VERSION ""

NS_ :

BS_:

BU_:

BO_ 3221225472 VECTOR__INDEPENDENT_SIG_MSG: 0 Vector__XXX
 SG_ fixSetG : 0|8@1+ (1,0) [0|15] "" Vector__XXX
 SG_ fixSetChrg : 0|8@1+ (1,0) [0|255] "" Vector__XXX
 SG_ NewSignal_0005 : 14|1@1+ (1,0) [0|0] "" Vector__XXX
 SG_ NewSignal_0006 : 15|1@1+ (1,0) [0|0] "" Vector__XXX
 SG_ NewSignal_0008 : 24|8@1+ (1,0) [0|0] "" Vector__XXX

BO_ 50 getData: 8 Vector__XXX
 SG_ Packet_ID M : 0|8@1+ (1,0) [0|3] "" Vector__XXX
 SG_ opMode m0 : 16|8@1+ (1,0) [0|15] "" Vector__XXX
 SG_ lowestCell m0 : 24|16@1+ (0.001,0) [0|5] "V" Vector__XXX
 SG_ highestCell m0 : 40|16@1+ (0.001,0) [0|5] "V" Vector__XXX
 SG_ highestTemp m0 : 56|8@1+ (1,0) [0|0] "C" Vector__XXX
 SG_ time_to_80_hh m1 : 16|8@1+ (1,0) [0|255] "hours" Vector__XXX
 SG_ time_to_80_mm m1 : 24|8@1+ (1,0) [0|59] "minutes" Vector__XXX
 SG_ batteryCapacity m1 : 32|8@1+ (1,0) [0|255] "Ah" Vector__XXX
 SG_ packVoltage m1 : 48|16@1+ (0.1,0) [0|1500] "V" Vector__XXX
 SG_ time_to_100_hh m2 : 16|8@1+ (1,0) [0|255] "hours" Vector__XXX
 SG_ time_to_100_mm m2 : 24|8@1+ (1,0) [0|59] "minutes" Vector__XXX
 SG_ current m2 : 32|16@1- (0.01,0) [0|2000] "A" Vector__XXX
 SG_ soc m2 : 48|8@1+ (1,0) [0|100] "" Vector__XXX
 SG_ soh m2 : 56|8@1+ (1,0) [0|100] "" Vector__XXX
 SG_ lv_error : 8|1@1+ (1,0) [0|1] "" Vector__XXX
 SG_ precharger_error : 9|1@1+ (1,0) [0|1] "" Vector__XXX
 SG_ contactor_fb_error : 10|1@1+ (1,0) [0|1] "" Vector__XXX
 SG_ battery_temp_error : 11|1@1+ (1,0) [0|1] "" Vector__XXX
 SG_ bms_comm_error : 12|1@1+ (1,0) [0|1] "" Vector__XXX
 SG_ disc_current_error : 13|1@1+ (1,0) [0|1] "" Vector__XXX
 SG_ chrg_current_error : 14|1@1+ (1,0) [0|1] "" Vector__XXX
 SG_ cell_balancing_error : 15|1@1+ (1,0) [0|1] "" Vector__XXX
 SG_ chrg_complete_flag m1 : 40|1@1+ (1,0) [0|1] "" Vector__XXX
 SG_ cv_mode m1 : 41|1@1+ (1,0) [0|1] "" Vector__XXX
 SG_ charge_current_lim m1 : 42|1@1+ (1,0) [0|1] "" Vector__XXX
 SG_ over_temp m1 : 43|1@1+ (1,0) [0|1] "" Vector__XXX
 SG_ low_soc m1 : 44|1@1+ (1,0) [0|1] "" Vector__XXX
 SG_ chiller_enable m1 : 45|1@1+ (1,0) [0|1] "" Vector__XXX
 SG_ charging m1 : 46|1@1+ (1,0) [0|1] "" Vector__XXX
 SG_ cell_hv_errpr m1 : 47|1@1+ (1,0) [0|1] "" Vector__XXX

BO_ 105 debugData: 8 Vector__XXX
 SG_ db_index M : 0|8@1+ (1,0) [0|11] "" Vector__XXX
 SG_ slave0_humidity m0 : 8|16@1+ (1,0) [0|100] "%" Vector__XXX
 SG_ slave0_temperature m0 : 24|16@1- (1,0) [-45|130] "*C" Vector__XXX
 SG_ slave0_open_wire m0 : 40|16@1+ (1,0) [0|65535] "" Vector__XXX
 SG_ slave1_humidity m1 : 8|16@1+ (1,0) [0|100] "%" Vector__XXX
 SG_ slave1_temperature m1 : 24|16@1- (1,0) [-45|130] "*C" Vector__XXX
 SG_ slave1_open_wire m1 : 40|16@1+ (1,0) [0|65535] "" Vector__XXX
 SG_ sht30_error m0 : 56|8@1+ (1,0) [0|255] "" Vector__XXX
 SG_ v_cell_0 m2 : 8|16@1+ (0.0001,0) [0|6.5535] "V" Vector__XXX
 SG_ v_cell_1 m2 : 24|16@1+ (0.0001,0) [0|6.5535] "V" Vector__XXX
 SG_ v_cell_2 m2 : 40|16@1+ (0.0001,0) [0|6.5535] "V" Vector__XXX
 SG_ v_cell_3 m3 : 8|16@1+ (0.0001,0) [0|6.5535] "V" Vector__XXX
 SG_ v_cell_4 m3 : 24|16@1+ (0.0001,0) [0|6.5535] "V" Vector__XXX
 SG_ v_cell_5 m3 : 40|16@1+ (0.0001,0) [0|6.5535] "V" Vector__XXX
 SG_ v_cell_6 m4 : 8|16@1+ (0.0001,0) [0|6.5535] "V" Vector__XXX
 SG_ v_cell_7 m4 : 24|16@1+ (0.0001,0) [0|6.5535] "V" Vector__XXX
 SG_ v_cell_8 m4 : 40|16@1+ (0.0001,0) [0|6.5535] "V" Vector__XXX
 SG_ v_cell_9 m5 : 8|16@1+ (0.0001,0) [0|6.5535] "V" Vector__XXX
 SG_ v_cell_10 m5 : 24|16@1+ (0.0001,0) [0|6.5535] "V" Vector__XXX
 SG_ v_cell_11 m5 : 40|16@1+ (0.0001,0) [0|6.5535] "V" Vector__XXX
 SG_ v_cell_12 m6 : 8|16@1+ (0.0001,0) [0|6.5535] "V" Vector__XXX
 SG_ v_cell_13 m6 : 24|16@1+ (0.0001,0) [0|6.5535] "V" Vector__XXX
 SG_ v_cell_14 m6 : 40|16@1+ (0.0001,0) [0|6.5535] "V" Vector__XXX
 SG_ v_cell_15 m7 : 8|16@1+ (0.0001,0) [0|6.5535] "V" Vector__XXX
 SG_ v_cell_16 m7 : 24|16@1+ (0.0001,0) [0|6.5535] "V" Vector__XXX
 SG_ v_cell_17 m7 : 40|16@1+ (0.0001,0) [0|6.5535] "V" Vector__XXX
 SG_ v_cell_18 m8 : 8|16@1+ (0.0001,0) [0|6.5535] "V" Vector__XXX
 SG_ v_cell_19 m8 : 24|16@1+ (0.0001,0) [0|6.5535] "V" Vector__XXX
 SG_ v_cell_20 m8 : 40|16@1+ (0.0001,0) [0|6.5535] "V" Vector__XXX
 SG_ v_cell_21 m9 : 8|16@1+ (0.0001,0) [0|6.5535] "V" Vector__XXX
 SG_ v_cell_22 m9 : 24|16@1+ (0.0001,0) [0|6.5535] "V" Vector__XXX
 SG_ v_cell_23 m9 : 40|16@1+ (0.0001,0) [0|6.5535] "V" Vector__XXX
 SG_ v_cell_24 m10 : 8|16@1+ (0.0001,0) [0|6.5535] "V" Vector__XXX
 SG_ v_cell_25 m10 : 24|16@1+ (0.0001,0) [0|6.5535] "V" Vector__XXX
 SG_ v_cell_26 m10 : 40|16@1+ (0.0001,0) [0|6.5535] "V" Vector__XXX
 SG_ v_cell_27 m11 : 8|16@1+ (0.0001,0) [0|6.5535] "V" Vector__XXX
 SG_ v_cell_28 m11 : 24|16@1+ (0.0001,0) [0|6.5535] "V" Vector__XXX
 SG_ v_cell_29 m11 : 40|16@1+ (0.0001,0) [0|6.5535] "V" Vector__XXX
 SG_ t_cell_0 m2 : 56|8@1+ (1,0) [0|255] "*C" Vector__XXX
 SG_ t_cell_1 m3 : 56|8@1+ (1,0) [0|255] "*C" Vector__XXX
 SG_ t_cell_2 m4 : 56|8@1+ (1,0) [0|255] "*C" Vector__XXX
 SG_ t_cell_3 m5 : 56|8@1+ (1,0) [0|255] "*C" Vector__XXX
 SG_ t_cell_4 m6 : 56|8@1+ (1,0) [0|255] "*C" Vector__XXX
 SG_ t_cell_5 m7 : 56|8@1+ (1,0) [0|255] "*C" Vector__XXX
 SG_ t_cell_6 m8 : 56|8@1+ (1,0) [0|255] "*C" Vector__XXX
 SG_ t_cell_7 m9 : 56|8@1+ (1,0) [0|255] "*C" Vector__XXX
 SG_ t_cell_8 m10 : 56|8@1+ (1,0) [0|255] "*C" Vector__XXX

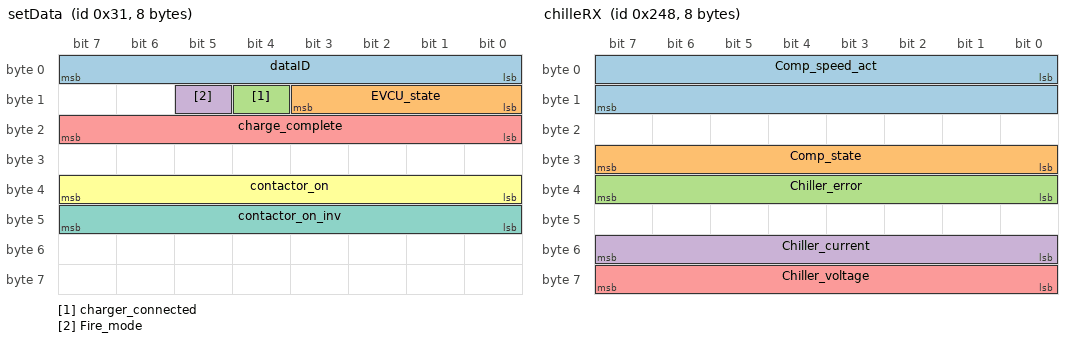
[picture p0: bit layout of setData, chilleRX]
BO_ 49 setData: 8 Vector__XXX
 SG_ dataID : 0|8@1+ (1,0) [0|2] "" Vector__XXX
 SG_ EVCU_state : 8|4@1+ (1,0) [0|8] "" Vector__XXX
 SG_ charger_connected : 12|1@1+ (1,0) [0|0] "" Vector__XXX
 SG_ Fire_mode : 13|1@1+ (1,0) [0|0] "" Vector__XXX
 SG_ charge_complete : 16|8@1+ (1,0) [0|0] "" Vector__XXX
 SG_ contactor_on : 32|8@1+ (1,0) [0|255] "" Vector__XXX
 SG_ contactor_on_inv : 40|8@1+ (1,0) [0|255] "" Vector__XXX

BO_ 584 chilleRX: 8 Vector__XXX
 SG_ Comp_speed_act : 0|16@1+ (1,0) [0|0] "" Vector__XXX
 SG_ Comp_state : 24|8@1+ (1,0) [0|0] "" Vector__XXX
 SG_ Chiller_error : 32|8@1+ (1,0) [0|0] "" Vector__XXX
 SG_ Chiller_current : 48|8@1+ (1,0) [0|0] "" Vector__XXX
 SG_ Chiller_voltage : 56|8@1+ (4,0) [0|0] "" Vector__XXX

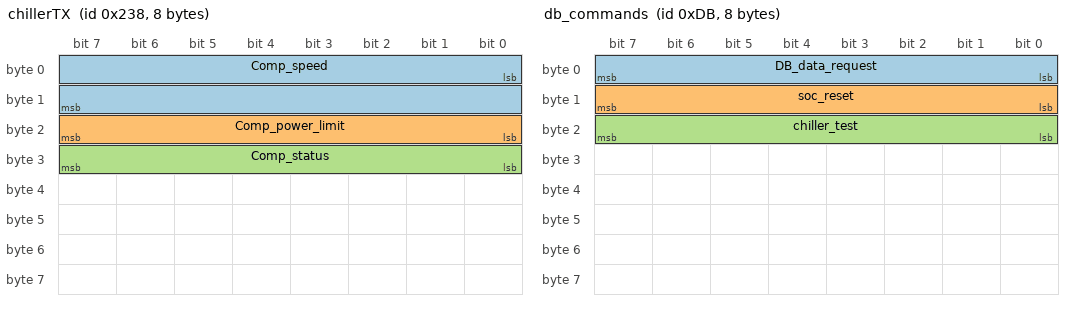
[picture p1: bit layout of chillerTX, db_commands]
BO_ 568 chillerTX: 8 Vector__XXX
 SG_ Comp_speed : 0|16@1+ (1,0) [0|0] "" Vector__XXX
 SG_ Comp_power_limit : 16|8@1+ (1,0) [0|0] "" Vector__XXX
 SG_ Comp_status : 24|8@1+ (1,0) [0|0] "" Vector__XXX

BO_ 219 db_commands: 8 Vector__XXX
 SG_ DB_data_request : 0|8@1+ (1,0) [0|0] "" Vector__XXX
 SG_ soc_reset : 8|8@1+ (1,0) [0|0] "" Vector__XXX
 SG_ chiller_test : 16|8@1+ (1,0) [0|0] "" Vector__XXX

BO_ 56 gbtData: 8 Vector__XXX
 SG_ GBT_Frame_ID M : 0|8@1+ (1,0) [0|13] "" Vector__XXX
 SG_ GBT_MaxChargeVoltage m0 : 8|16@1+ (0.1,0) [0|6553.5] "V" Vector__XXX
 SG_ GBT_MaxCellChargeVoltage m0 : 24|16@1+ (0.01,0) [0|655.35] "V" Vector__XXX
 SG_ GBT_RatedVoltage m0 : 40|16@1+ (0.1,0) [0|6553.5] "V" Vector__XXX
 SG_ GBT_BatteryType m0 : 56|8@1+ (1,0) [0|255] "" Vector__XXX
 SG_ GBT_TotalEnergy m1 : 8|16@1+ (0.1,0) [0|6553.5] "kWh" Vector__XXX
 SG_ GBT_MaxPermitTemp m1 : 24|16@1- (0.1,0) [-3276.8|3276.7] "C" Vector__XXX
 SG_ GBT_HighestCellID m1 : 56|8@1+ (1,0) [0|255] "" Vector__XXX
 SG_ GBT_LowestTemp m2 : 8|16@1- (0.1,0) [-3276.8|3276.7] "C" Vector__XXX
 SG_ GBT_LowestTempProbe m2 : 24|8@1+ (1,0) [0|255] "" Vector__XXX
 SG_ GBT_HighestTempProbe m2 : 32|8@1+ (1,0) [0|255] "" Vector__XXX
 SG_ GBT_CellVoltageState m2 : 40|2@1+ (1,0) [0|3] "" Vector__XXX
 SG_ GBT_SocState m2 : 42|2@1+ (1,0) [0|3] "" Vector__XXX
 SG_ GBT_ChargeOverCurrent m2 : 44|2@1+ (1,0) [0|3] "" Vector__XXX
 SG_ GBT_BatteryTempState m2 : 46|2@1+ (1,0) [0|3] "" Vector__XXX
 SG_ GBT_InsulationState m2 : 48|2@1+ (1,0) [0|3] "" Vector__XXX
 SG_ GBT_SingleCellVoltages m2 : 50|2@1+ (1,0) [0|3] "" Vector__XXX
 SG_ GBT_SingleCellTemps m2 : 52|2@1+ (1,0) [0|3] "" Vector__XXX
 SG_ GBT_BmsTempState m2 : 54|2@1+ (1,0) [0|3] "" Vector__XXX
 SG_ GBT_FcContactorState m2 : 56|2@1+ (1,0) [0|3] "" Vector__XXX
 SG_ GBT_LowestCellID m3 : 8|8@1+ (1,0) [0|255] "" Vector__XXX
 SG_ GBT_V_Cell_01 m4 : 8|16@1+ (0.01,0) [0|655.35] "V" Vector__XXX
 SG_ GBT_V_Cell_02 m4 : 24|16@1+ (0.01,0) [0|655.35] "V" Vector__XXX
 SG_ GBT_V_Cell_03 m4 : 40|16@1+ (0.01,0) [0|655.35] "V" Vector__XXX
 SG_ GBT_V_Cell_04 m5 : 8|16@1+ (0.01,0) [0|655.35] "V" Vector__XXX
 SG_ GBT_V_Cell_05 m5 : 24|16@1+ (0.01,0) [0|655.35] "V" Vector__XXX
 SG_ GBT_V_Cell_06 m5 : 40|16@1+ (0.01,0) [0|655.35] "V" Vector__XXX
 SG_ GBT_V_Cell_07 m6 : 8|16@1+ (0.01,0) [0|655.35] "V" Vector__XXX
 SG_ GBT_V_Cell_08 m6 : 24|16@1+ (0.01,0) [0|655.35] "V" Vector__XXX
 SG_ GBT_V_Cell_09 m6 : 40|16@1+ (0.01,0) [0|655.35] "V" Vector__XXX
 SG_ GBT_V_Cell_10 m7 : 8|16@1+ (0.01,0) [0|655.35] "V" Vector__XXX
 SG_ GBT_V_Cell_11 m7 : 24|16@1+ (0.01,0) [0|655.35] "V" Vector__XXX
 SG_ GBT_V_Cell_12 m7 : 40|16@1+ (0.01,0) [0|655.35] "V" Vector__XXX
 SG_ GBT_V_Cell_13 m8 : 8|16@1+ (0.01,0) [0|655.35] "V" Vector__XXX
 SG_ GBT_V_Cell_14 m8 : 24|16@1+ (0.01,0) [0|655.35] "V" Vector__XXX
 SG_ GBT_V_Cell_15 m8 : 40|16@1+ (0.01,0) [0|655.35] "V" Vector__XXX
 SG_ GBT_V_Cell_16 m9 : 8|16@1+ (0.01,0) [0|655.35] "V" Vector__XXX
 SG_ GBT_V_Cell_17 m9 : 24|16@1+ (0.01,0) [0|655.35] "V" Vector__XXX
 SG_ GBT_V_Cell_18 m9 : 40|16@1+ (0.01,0) [0|655.35] "V" Vector__XXX
 SG_ GBT_V_Cell_19 m10 : 8|16@1+ (0.01,0) [0|655.35] "V" Vector__XXX
 SG_ GBT_V_Cell_20 m10 : 24|16@1+ (0.01,0) [0|655.35] "V" Vector__XXX
 SG_ GBT_V_Cell_21 m10 : 40|16@1+ (0.01,0) [0|655.35] "V" Vector__XXX
 SG_ GBT_V_Cell_22 m11 : 8|16@1+ (0.01,0) [0|655.35] "V" Vector__XXX
 SG_ GBT_V_Cell_23 m11 : 24|16@1+ (0.01,0) [0|655.35] "V" Vector__XXX
 SG_ GBT_V_Cell_24 m11 : 40|16@1+ (0.01,0) [0|655.35] "V" Vector__XXX
 SG_ GBT_V_Cell_25 m12 : 8|16@1+ (0.01,0) [0|655.35] "V" Vector__XXX
 SG_ GBT_V_Cell_26 m12 : 24|16@1+ (0.01,0) [0|655.35] "V" Vector__XXX
 SG_ GBT_V_Cell_27 m12 : 40|16@1+ (0.01,0) [0|655.35] "V" Vector__XXX
 SG_ GBT_V_Cell_28 m13 : 8|16@1+ (0.01,0) [0|655.35] "V" Vector__XXX
 SG_ GBT_V_Cell_29 m13 : 24|16@1+ (0.01,0) [0|655.35] "V" Vector__XXX
 SG_ GBT_V_Cell_30 m13 : 40|16@1+ (0.01,0) [0|655.35] "V" Vector__XXX
 SG_ GBT_T_Probe_1 m4 : 56|8@1+ (1,0) [0|255] "C" Vector__XXX
 SG_ GBT_T_Probe_2 m5 : 56|8@1+ (1,0) [0|255] "C" Vector__XXX
 SG_ GBT_T_Probe_3 m6 : 56|8@1+ (1,0) [0|255] "C" Vector__XXX
 SG_ GBT_T_Probe_4 m7 : 56|8@1+ (1,0) [0|255] "C" Vector__XXX
 SG_ GBT_T_Probe_5 m8 : 56|8@1+ (1,0) [0|255] "C" Vector__XXX
 SG_ GBT_T_Probe_6 m9 : 56|8@1+ (1,0) [0|255] "C" Vector__XXX
 SG_ GBT_T_Probe_7 m10 : 56|8@1+ (1,0) [0|255] "C" Vector__XXX
 SG_ GBT_T_Probe_8 m11 : 56|8@1+ (1,0) [0|255] "C" Vector__XXX
 SG_ GBT_T_Probe_9 m12 : 56|8@1+ (1,0) [0|255] "C" Vector__XXX

BO_ 53 eepromData: 8 Vector__XXX
 SG_ EEP_Page_ID M : 0|8@1+ (1,0) [1|5] "" Vector__XXX
 SG_ EEP_NominalCapacity m1 : 8|32@1+ (1,0) [0|4294967295] "Ah" Vector__XXX
 SG_ EEP_CapacityHealth m1 : 56|8@1+ (1,0) [0|1] "" Vector__XXX
 SG_ EEP_ChargeCurrentLimit m2 : 8|16@1+ (1,0) [0|65535] "A" Vector__XXX
 SG_ EEP_DischargeCurrentLimit m2 : 24|16@1+ (1,0) [0|65535] "A" Vector__XXX
 SG_ EEP_ShortCircuitLimit m2 : 40|16@1+ (1,0) [0|65535] "A" Vector__XXX
 SG_ EEP_CurrentsHealth m2 : 56|8@1+ (1,0) [0|1] "" Vector__XXX
 SG_ EEP_FwPrefix1 m3 : 8|8@1+ (1,0) [0|255] "" Vector__XXX
 SG_ EEP_FwPrefix2 m3 : 16|8@1+ (1,0) [0|255] "" Vector__XXX
 SG_ EEP_FwPrefix3 m3 : 24|8@1+ (1,0) [0|255] "" Vector__XXX
 SG_ EEP_FwPrefix4 m3 : 32|8@1+ (1,0) [0|255] "" Vector__XXX
 SG_ EEP_FwMajor m3 : 40|8@1+ (1,0) [0|255] "" Vector__XXX
 SG_ EEP_FwMinor m3 : 48|8@1+ (1,0) [0|255] "" Vector__XXX
 SG_ EEP_FwPatch m3 : 56|8@1+ (1,0) [0|255] "" Vector__XXX
 SG_ EEP_PackPrefix1 m4 : 8|8@1+ (1,0) [0|255] "" Vector__XXX
 SG_ EEP_PackPrefix2 m4 : 16|8@1+ (1,0) [0|255] "" Vector__XXX
 SG_ EEP_PackPrefix3 m4 : 24|8@1+ (1,0) [0|255] "" Vector__XXX
 SG_ EEP_PackYear m4 : 32|8@1+ (1,0) [0|255] "" Vector__XXX
 SG_ EEP_PackMonth m4 : 40|8@1+ (1,0) [0|255] "" Vector__XXX
 SG_ EEP_PackSerial m4 : 55|16@0+ (1,0) [0|65535] "" Vector__XXX
 SG_ EEP_FwUpdateYear m5 : 8|8@1+ (1,0) [0|255] "" Vector__XXX
 SG_ EEP_FwUpdateMonth m5 : 16|8@1+ (1,0) [0|255] "" Vector__XXX
 SG_ EEP_FwUpdateDay m5 : 24|8@1+ (1,0) [0|255] "" Vector__XXX

CM_ BO_ 3221225472 "This is a message for not used signals, created by Vector CANdb++ DBC OLE DB Provider.";
CM_ SG_ 3221225472 fixSetG "BMS error flags";
CM_ SG_ 3221225472 fixSetChrg "Charge status flags";
CM_ BO_ 50 "BMS controller";
CM_ SG_ 50 Packet_ID "Multiplexor ID";
CM_ SG_ 50 opMode "BMS operating mode
";
CM_ SG_ 50 lowestCell "Lowest cell voltage
";
CM_ SG_ 50 highestCell "Highest cell voltage";
CM_ SG_ 50 highestTemp "Highest cell temperature";
CM_ SG_ 50 time_to_80_hh "Time (HH) to charge to 80%";
CM_ SG_ 50 time_to_80_mm "Time (MM) to charge to 80%";
CM_ SG_ 50 batteryCapacity "Total battery capacity available";
CM_ SG_ 50 packVoltage "Pack voltage";
CM_ SG_ 50 time_to_100_hh "Time (HH) to full charge";
CM_ SG_ 50 time_to_100_mm "Time (MM) to full charge";
CM_ SG_ 50 current "Battery current";
CM_ SG_ 50 soc "State of charge of the battery";
CM_ SG_ 50 soh "State of health of the battery";
CM_ SG_ 50 lv_error "Low voltage error flag
";
CM_ SG_ 50 precharger_error "Precharger error flag";
CM_ SG_ 50 contactor_fb_error "Contactor feedback error flag";
CM_ SG_ 50 battery_temp_error "Battery high temperature error flag";
CM_ SG_ 50 bms_comm_error "BMS internal communication error flag";
CM_ SG_ 50 disc_current_error "Overcurrent (discharge) flag";
CM_ SG_ 50 chrg_current_error "Overcurrent (charge) flag";
CM_ SG_ 50 cell_balancing_error "Cell balancing error flag";
CM_ SG_ 50 chrg_complete_flag "Charge complete flag";
CM_ SG_ 50 cv_mode "Constant voltage mode flag";
CM_ SG_ 50 charge_current_lim "Charge current limit exceeded flag";
CM_ SG_ 50 over_temp "High temperature warning flag during charge ";
CM_ SG_ 50 low_soc "Low SOC warning during charge flag";
CM_ SG_ 50 chiller_enable "Chiller enable command";
CM_ SG_ 50 charging "Charging status flag";
CM_ SG_ 50 cell_hv_errpr "Cell high voltage error";
CM_ BO_ 105 "BMS debug data dump
";
CM_ SG_ 105 db_index "Multiplexor ID
";
CM_ BO_ 49 "EVCU data to BMS
";
CM_ BO_ 584 "Chiller data feedback
";
CM_ BO_ 568 "Chiller commands
";
CM_ BO_ 56 "GB/T 27930 charging data to EVCC (PDU_gbt_Data_write). Sent only while GBT_connected and contactor closed / fast charging. SOC, pack voltage, highest / lowest cell voltage, highest temperature, remaining time: see getData (0x32). Charge current limit, rated capacity: see eepromData (0x35).";
CM_ SG_ 56 GBT_Frame_ID "Frame index: 0..3 status frames, 4.. = 3 cell voltages + 1 temperature";
CM_ SG_ 56 GBT_MaxChargeVoltage "Max charging voltage = max cell charge voltage x series cells";
CM_ SG_ 56 GBT_MaxCellChargeVoltage "Max charging voltage of single cell (HIGHEST_CELL_VOLTAGE_LIMIT)";
CM_ SG_ 56 GBT_RatedVoltage "Rated (nominal) pack voltage = nominal cell voltage x series cells";
CM_ SG_ 56 GBT_BatteryType "GB/T battery type code";
CM_ SG_ 56 GBT_TotalEnergy "Total energy = rated voltage x nominal capacity";
CM_ SG_ 56 GBT_MaxPermitTemp "Max permissible temperature (HIGHEST_TEMPERATURE_LIMIT)";
CM_ SG_ 56 GBT_HighestCellID "Highest voltage cell number in series, 1-based";
CM_ SG_ 56 GBT_LowestTemp "Lowest cell temperature";
CM_ SG_ 56 GBT_LowestTempProbe "Lowest temperature probe number, 1-based, per IC";
CM_ SG_ 56 GBT_HighestTempProbe "Highest temperature probe number, 1-based, per IC";
CM_ SG_ 56 GBT_CellVoltageState "status_A: pack cell voltage state";
CM_ SG_ 56 GBT_SocState "status_A: SOC state (>70% over high, <20% below low)";
CM_ SG_ 56 GBT_ChargeOverCurrent "status_A: charging over current state";
CM_ SG_ 56 GBT_BatteryTempState "status_A: battery temperature state";
CM_ SG_ 56 GBT_InsulationState "status_B: insulation state (hard coded normal, not implemented)";
CM_ SG_ 56 GBT_SingleCellVoltages "status_B: single cell voltages state (not set in firmware)";
CM_ SG_ 56 GBT_SingleCellTemps "status_B: single cell temperatures state (not set in firmware)";
CM_ SG_ 56 GBT_BmsTempState "status_B: BMS MCU temperature state";
CM_ SG_ 56 GBT_FcContactorState "status_C: charge contactor state";
CM_ SG_ 56 GBT_LowestCellID "Lowest voltage cell number in series, 1-based";
CM_ SG_ 105 slave0_open_wire "Open wire bits, IC 0 (open_wire_msb:lsb)";
CM_ SG_ 105 slave1_open_wire "Open wire bits, IC 1 (open_wire_msb:lsb)";
CM_ SG_ 105 v_cell_0 "Series cell number, 0-based, unused positions (CELL_UNUSED) skipped. 0xFFFF = no cell";
CM_ SG_ 105 t_cell_0 "Temperature probes (ic x TEMP_PER_IC + t), 0-based. 0xFF = no probe";
CM_ BO_ 53 "EEPROM configuration broadcast (broadcast_eeprom_data_over_can), every 10th CAN task pass, pages 1..5";
CM_ SG_ 53 EEP_Page_ID "Multiplexor page 1..5";
CM_ SG_ 53 EEP_ChargeCurrentLimit "Charge current limit, positive (CHARGE_CURRENT_THRESHOLD / -100)";
CM_ SG_ 53 EEP_PackYear "BCD, e.g. 0x26 = 2026";
CM_ SG_ 53 EEP_FwUpdateYear "BCD, e.g. 0x26 = 2026";
BA_DEF_ BO_  "VFrameFormat" ENUM  "StandardCAN","ExtendedCAN","reserved","J1939PG";
BA_DEF_  "DatabaseVersion" STRING ;
BA_DEF_  "BusType" STRING ;
BA_DEF_  "ProtocolType" STRING ;
BA_DEF_  "DatabaseCompiler" STRING ;
BA_DEF_DEF_  "VFrameFormat" "J1939PG";
BA_DEF_DEF_  "DatabaseVersion" "DEMO PLUS";
BA_DEF_DEF_  "BusType" "";
BA_DEF_DEF_  "ProtocolType" "";
BA_DEF_DEF_  "DatabaseCompiler" "";
BA_ "DatabaseVersion" "1.0.0";
BA_ "DatabaseCompiler" "CSS ELECTRONICS (WWW.CSSELECTRONICS.COM)";
BA_ "BusType" "CAN";
BA_ "ProtocolType" "J1939";
BA_ "VFrameFormat" BO_ 50 0;
BA_ "VFrameFormat" BO_ 105 0;
BA_ "VFrameFormat" BO_ 49 0;
BA_ "VFrameFormat" BO_ 584 0;
BA_ "VFrameFormat" BO_ 568 0;
BA_ "VFrameFormat" BO_ 219 0;
BA_ "VFrameFormat" BO_ 56 0;
BA_ "VFrameFormat" BO_ 53 0;
VAL_ 56 GBT_BatteryType 1 "Lead acid" 2 "NiMH" 3 "LFP" 4 "LMO" 5 "LCO" 6 "Ternary" 7 "Polymer Li-ion" 8 "Li titanate" 255 "Other" ;
VAL_ 56 GBT_CellVoltageState 0 "Normal" 1 "Over high" 2 "Below low" 3 "Reserved" ;
VAL_ 56 GBT_SocState 0 "Normal" 1 "Over high" 2 "Below low" 3 "Reserved" ;
VAL_ 56 GBT_ChargeOverCurrent 0 "Normal" 1 "Over current" 2 "Untrusted" 3 "Reserved" ;
VAL_ 56 GBT_BatteryTempState 0 "Normal" 1 "Over high" 2 "Untrusted" 3 "Reserved" ;
VAL_ 56 GBT_InsulationState 0 "Normal" 1 "Abnormal" 2 "Untrusted" 3 "Reserved" ;
VAL_ 56 GBT_SingleCellVoltages 0 "Normal" 1 "Over high" 2 "Below low" 3 "Reserved" ;
VAL_ 56 GBT_SingleCellTemps 0 "Normal" 1 "Over high" 2 "Below low" 3 "Reserved" ;
VAL_ 56 GBT_BmsTempState 0 "Normal" 1 "Over high" 2 "Untrusted" 3 "Reserved" ;
VAL_ 56 GBT_FcContactorState 0 "Normal" 1 "Abnormal" 2 "Untrusted" 3 "Reserved" ;
VAL_ 53 EEP_CapacityHealth 0 "OK" 1 "Default loaded" ;
VAL_ 53 EEP_CurrentsHealth 0 "OK" 1 "Default loaded" ;
